# STM32MP21_CA35 register map
File version: 0.4
CPU: CM33 r0p1, little endian, MPU, FPU, vendor SysTick, 8 interrupt priority bits
Registers are 32-bit, read-write, reset 0x0 unless marked. A register's access mark holds for its fields unless they carry their own. Offsets are from the block's base; [hi:lo] are bit positions; {n}, {i} and the like mark numbered series; 'fields as' and 'values as' point back to an identical list.

## RCC (part 2 of 2) — RCC register block
Base 0x44200000
Same registers: RCC_S 0x54200000
0x4E0 RCC_DDRPHYCCFGR — RCC DDRPHYC configuration register
  [1] DDRPHYCEN — DDRPHYC kernel clock enable
    0=Writing 0 disables DDRPHYC kernel clock; 1=Writing 1 enables DDRPHYC kernel clock
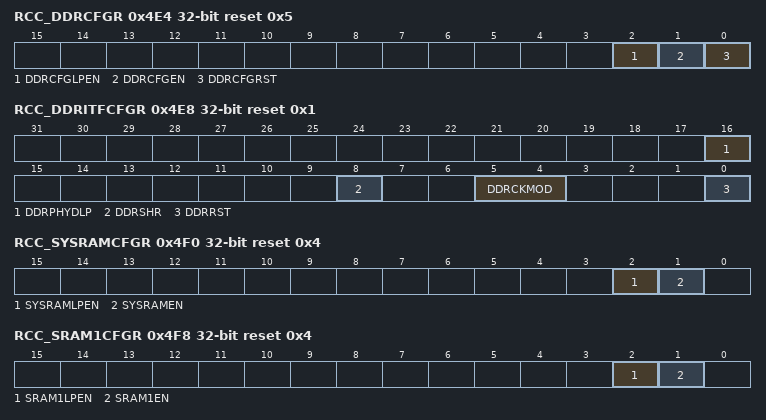
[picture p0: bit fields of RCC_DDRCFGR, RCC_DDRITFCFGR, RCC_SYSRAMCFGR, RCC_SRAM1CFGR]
0x4E4 RCC_DDRCFGR reset 0x5 — RCC DDR configuration register
  [2] DDRCFGLPEN — DDR APB configuration clock enable during CSleep
    0=Writing 0 disables peripheral clocks in CSleep; 1=Writing 1 enables peripheral clocks in CSleep
  [1] DDRCFGEN — DDR APB configuration clock enable
    0=Writing 0 disables peripheral clocks; 1=Writing 1 enables peripheral clocks
  [0] DDRCFGRST — DDR APB configuration reset
    0=Writing 0 releases DDR APB configuration interface reset; 1=Writing 1 sets DDR APB configuration interface under reset
0x4E8 RCC_DDRITFCFGR reset 0x1 — RCC DDR interface configuration register
  [16] DDRPHYDLP — DDRPHY deep low-power mode (LP2 or LP3)
    0=DDRPHY not set in low-power mode (default after reset); 1=DDRPHY set in deep low-power mode
  [8] DDRSHR — DDR peripheral mode
    0=DDR defined as single peripheral (default after reset); 1=DDR defined as shared peripheral
  [5:4] DDRCKMOD — RCC mode for DDR clock control
    0=Normal mode: dphy_ker_ck and dphy_ker_byp_ck gating depends on DDRPHYCEN, DDRSHR, DDRPHYDLP, and CPU1 or system mode; 1=ASR (automatic self-refresh) mode: ddrc_ker_ck is gated automatically according to cactive_ddrc signal; 2=HSR (hardware self-refresh) mode: ddrc_ker_ck gating depends on DDRCPEN, DDRCLPEN, DDRSHR, and CPU1 or system mode
  [0] DDRRST — DDR core and PHY reset
    0=DDR core and PHY are not reset; 1=DDR core and PHY are reset (default after reset)
0x4F0 RCC_SYSRAMCFGR reset 0x4 — RCC SYSRAM configuration register
  [2] SYSRAMLPEN — SYSRAM clock enable during CSleep
    values as RCC_DDRCFGR.DDRCFGLPEN
  [1] SYSRAMEN — SYSRAM clock enable
    values as RCC_DDRCFGR.DDRCFGEN
0x4F8 RCC_SRAM1CFGR reset 0x4 — RCC SRAM1 configuration register
  [2] SRAM1LPEN — SRAM1 clock enable during CSleep
    values as RCC_DDRCFGR.DDRCFGLPEN
  [1] SRAM1EN — SRAM1 clock enable
    values as RCC_DDRCFGR.DDRCFGEN
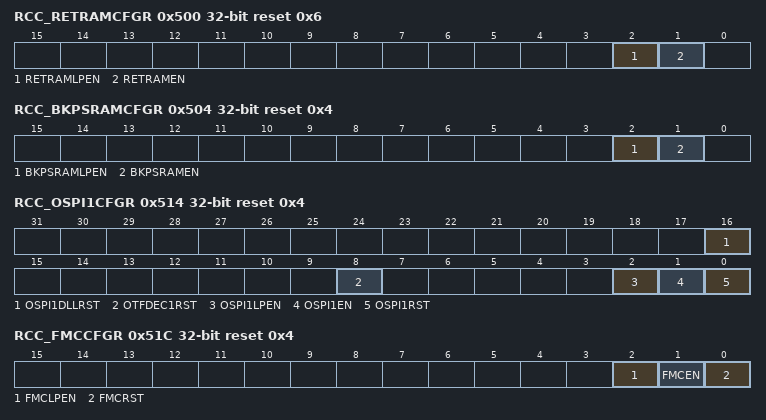
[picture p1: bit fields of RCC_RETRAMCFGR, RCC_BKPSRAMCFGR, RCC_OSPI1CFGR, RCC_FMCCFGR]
0x500 RCC_RETRAMCFGR reset 0x6 — RCC RETRAM configuration register
  [2] RETRAMLPEN — RETRAM clock enable during CSleep
    values as RCC_DDRCFGR.DDRCFGLPEN
  [1] RETRAMEN — RETRAM clock enable
    values as RCC_DDRCFGR.DDRCFGEN
0x504 RCC_BKPSRAMCFGR reset 0x4 — RCC BKPSRAM configuration register
  [2] BKPSRAMLPEN — BKPSRAM clock enable during CSleep
    values as RCC_DDRCFGR.DDRCFGLPEN
  [1] BKPSRAMEN — BKPSRAM clock enable
    values as RCC_DDRCFGR.DDRCFGEN
0x514 RCC_OSPI1CFGR reset 0x4 — RCC OCTOSPI1 configuration register
  [16] OSPI1DLLRST — OCTOSPI1 DLL reset
    0=Writing 0 releases OCTOSPI1 DLL reset; 1=Writing 1 asserts OCTOSPI1 DLL reset
  [8] OTFDEC1RST — OTFDEC1 reset
    0=Writing 0 releases OTFDEC1 reset; 1=Writing 1 asserts OTFDEC1 reset
  [2] OSPI1LPEN — OCTOSPI1, OTFDEC1 and OCTOSPI1 delay (DLYBOSPI1) clock enable duringCSleep
    values as RCC_DDRCFGR.DDRCFGLPEN
  [1] OSPI1EN — OCTOSPI1 and OTFDEC1 clock enable
    values as RCC_DDRCFGR.DDRCFGEN
  [0] OSPI1RST — OCTOSPI1 reset
    0=Writing 0 releases OCTOSPI1 reset; 1=Writing 1 asserts OCTOSPI1 reset
0x51C RCC_FMCCFGR reset 0x4 — RCC FMC configuration register
  [2] FMCLPEN — FMC clock enable during CSleep
    values as RCC_DDRCFGR.DDRCFGLPEN
  [1] FMCEN — FMC clock enable
    values as RCC_DDRCFGR.DDRCFGEN
  [0] FMCRST — FMC reset
    0=Writing 0 releases FMC reset; 1=Writing 1 asserts FMC reset
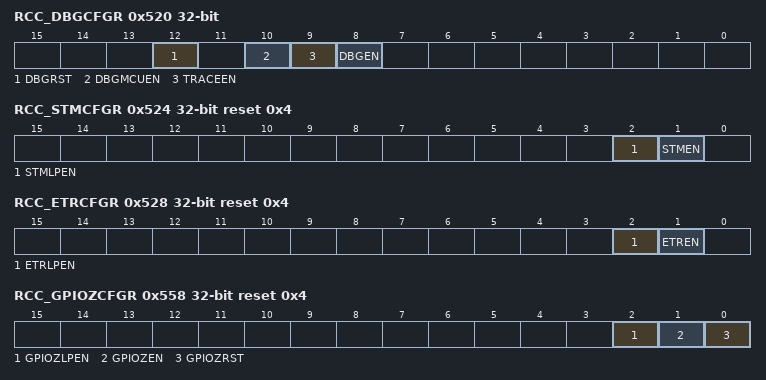
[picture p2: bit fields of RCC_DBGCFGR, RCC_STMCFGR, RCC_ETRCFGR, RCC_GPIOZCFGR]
0x520 RCC_DBGCFGR — RCC debug configuration register
  [12] DBGRST — Debug function reset
    0=Trace and debug parts are not reset (default after reset); 1=Trace and debug parts are under reset
  [10] DBGMCUEN — Clock enable for dbgmcu
    0=Clock for dbgmcu function disabled (default after reset); 1=Clock for dbgmcu function enabled
  [9] TRACEEN — Clock enable for trace port interface
    0=Clock for trace function disabled (default after reset); 1=Clock for trace function enabled
  [8] DBGEN — Debug function clock enable
    0=Enabling of clocks for debug function is controlled by cdbgpwrupreq signal from DAP (default after reset); 1=Clocks for debug function are enabled
0x524 RCC_STMCFGR reset 0x4 — RCC STM configuration register
  [2] STMLPEN — STM clock enable during CSleep
    values as RCC_DDRCFGR.DDRCFGLPEN
  [1] STMEN — STM clock enable
    values as RCC_DDRCFGR.DDRCFGEN
0x528 RCC_ETRCFGR reset 0x4 — RCC ETR configuration register
  [2] ETRLPEN — ETR clock enable during CSleep
    values as RCC_DDRCFGR.DDRCFGLPEN
  [1] ETREN — ETR clocks enable
    values as RCC_DDRCFGR.DDRCFGEN
0x558 RCC_GPIOZCFGR reset 0x4 — RCC GPIOZ configuration register
  [2] GPIOZLPEN — GPIOZ clock enable during CSleep
    values as RCC_DDRCFGR.DDRCFGLPEN
  [1] GPIOZEN — GPIOZ clock enable
    values as RCC_DDRCFGR.DDRCFGEN
  [0] GPIOZRST — GPIOZ reset
    0=Writing 0 releases GPIOZ reset; 1=Writing 1 asserts GPIOZ reset
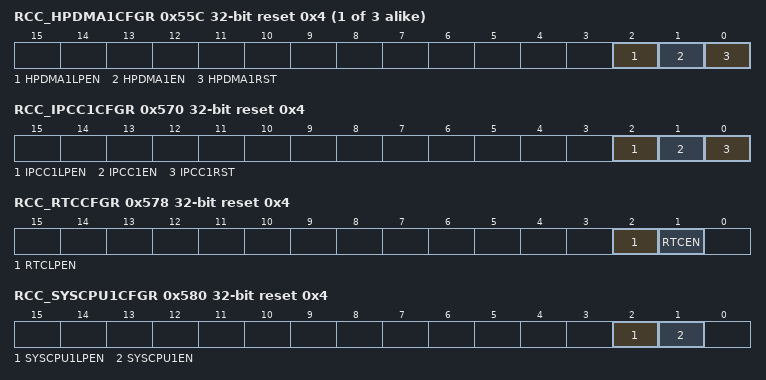
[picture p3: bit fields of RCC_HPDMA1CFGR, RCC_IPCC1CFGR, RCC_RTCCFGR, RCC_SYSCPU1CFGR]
{0x558+4i} RCC_HPDMA{i}CFGR reset 0x4 (i=1..3) — RCC HPDMA{i} configuration register
  [2] HPDMA{i}LPEN — HPDMA{i} clock enable during CSleep
    values as RCC_DDRCFGR.DDRCFGLPEN
  [1] HPDMA{i}EN — HPDMA{i} clock enable
    values as RCC_DDRCFGR.DDRCFGEN
  [0] HPDMA{i}RST — HPDMA{i} reset
    0=Writing 0 releases HPDMA{i} reset; 1=Writing 1 asserts HPDMA{i} reset
0x570 RCC_IPCC1CFGR reset 0x4 — RCC IPCC1 configuration register
  [2] IPCC1LPEN — IPCC1 clock enable during CSleep
    values as RCC_DDRCFGR.DDRCFGLPEN
  [1] IPCC1EN — IPCC1 clock enable
    values as RCC_DDRCFGR.DDRCFGEN
  [0] IPCC1RST — IPCC1 reset
    0=Writing 0 releases IPCC1 reset; 1=Writing 1 asserts IPCC1 reset
0x578 RCC_RTCCFGR reset 0x4 — RCC RTC configuration register
  [2] RTCLPEN — RTC bus clock enable during CSleep
    0=Writing 0 disables APB clock in CSleep; 1=Writing 1 enables APB clock in CSleep
  [1] RTCEN — RTC bus clock enable
    0=Writing 0 disables APB clock; 1=Writing 1 enables APB clock
0x580 RCC_SYSCPU1CFGR reset 0x4 — RCC SYSCPU1 configuration register
  [2] SYSCPU1LPEN — CPU1 system configuration clock enable during CSleep
    values as RCC_RTCCFGR.RTCLPEN
  [1] SYSCPU1EN — CPU1 system configuration clock enable
    values as RCC_RTCCFGR.RTCEN
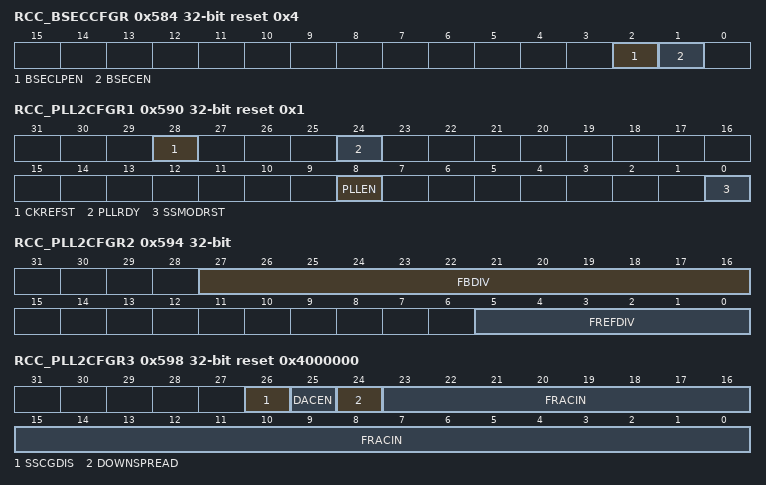
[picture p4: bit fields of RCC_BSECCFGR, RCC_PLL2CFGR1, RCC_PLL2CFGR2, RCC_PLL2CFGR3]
0x584 RCC_BSECCFGR reset 0x4 — RCC BSEC configuration register
  [2] BSECLPEN — BSEC clock enable during CSleep
    values as RCC_RTCCFGR.RTCLPEN
  [1] BSECEN — BSEC clock enable
    values as RCC_RTCCFGR.RTCEN
0x590 RCC_PLL2CFGR1 reset 0x1 — RCC PLL2 configuration register 1
  [28] CKREFST — PLL2 reference clock state
    0=Reading 0 means that PLL2 reference clock is not running; 1=Reading 1 means that PLL2 reference clock is running
  [24] PLLRDY ro — PLL2 clock ready flag
    0=PLL2 unlocked (default after reset); 1=PLL2 locked
  [8] PLLEN — PLL2 enable
    0=PLL2 off (default after reset); 1=PLL2 on
  [0] SSMODRST — PLL2 spread-spectrum modulator reset
    0=PLL2 spread-spectrum modulator reset module is released; 1=PLL2 spread-spectrum modulator reset module is asserted (default after reset)
0x594 RCC_PLL2CFGR2 — RCC PLL2 configuration register 2
  [27:16] FBDIV — PLL2 VCO multiplication factor
  [5:0] FREFDIV — PLL2 reference input clock divide frequency ratio
    0=Not applicable when PLL2 is enabled; 1=FREF divided by 1 (min value); 2=FREF divided by 2; 3=FREF divided by 3; {v}=FREF divided by {v} (v=60..63)
0x598 RCC_PLL2CFGR3 reset 0x4000000 — RCC PLL2 configuration register 3
  [26] SSCGDIS — PLL2 spread-spectrum modulator enable
    0=PLL2 spread-spectrum modulator enabled; 1=PLL2 spread-spectrum modulator disabled (default after reset)
  [25] DACEN — PLL2 noise canceling DAC enable in fractional mode
    0=DAC not active (default after reset); 1=DAC active
  [24] DOWNSPREAD — PLL2 VCO frequency modulation mode
    0=Center-spread modulation selected (default after reset); 1=Down-spread modulation selected
  [23:0] FRACIN — Fractional part of PLL2 VCO multiplication factor
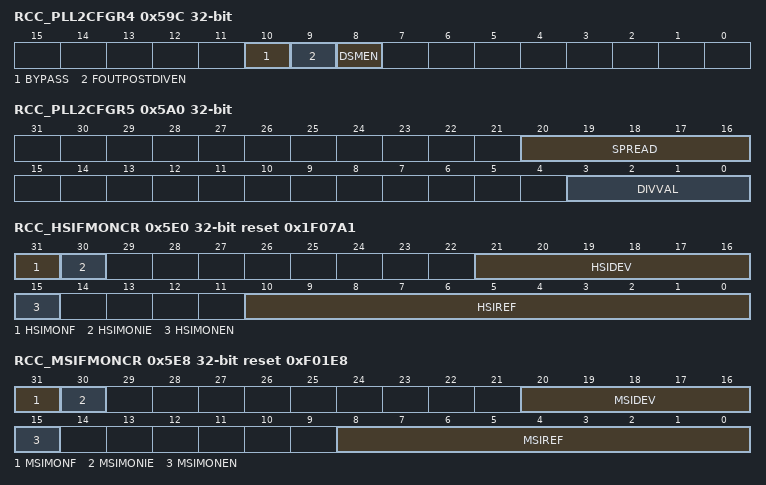
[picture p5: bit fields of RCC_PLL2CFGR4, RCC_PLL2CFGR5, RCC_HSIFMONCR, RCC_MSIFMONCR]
0x59C RCC_PLL2CFGR4 — RCC PLL2 configuration register 4
  [10] BYPASS — PLL2 FOUTPOSTDIV bypass
    0=FOUTPOSTDIV driven by POSTDIV2; 1=FOUTPOSTDIV driven by FREF
  [9] FOUTPOSTDIVEN — PLL2 output and post divider enable
    0=FOUTPOSTDIV output, POSTDIV1, and POSTDIV2 are powered down; 1=FOUTPOSTDIV output, POSTDIV1, and POSTDIV2 dividers are active
  [8] DSMEN — PLL2 delta-sigma modulator enable
    0=DSM is powered down; 1=DSM is active
0x5A0 RCC_PLL2CFGR5 — RCC PLL2 configuration register 5
  [20:16] SPREAD — Modulation depth adjustment for PLL2
  [3:0] DIVVAL — Modulation frequency adjustment for PLL2
0x5A8 RCC_PLL2CFGR6 — RCC PLL2 configuration register 6
  [2:0] POSTDIV1 — PLL2 VCO frequency divide level 1
    0=Not applicable; 1=FOUTVCO divided by 1 (minimum value); 6=FOUTVCO divided by 6; 7=FOUTVCO divided by 7
0x5AC RCC_PLL2CFGR7 — RCC PLL2 configuration register 7
  [2:0] POSTDIV2 — PLL2 VCO frequency divide level 2
    0=Not applicable; 1=FOUTVCO/POSTDIV1 divided by 1 (minimum value); 6=FOUTVCO/POSTDIV1 divided by 6; 7=FOUTVCO/POSTDIV1 divided by 7
0x5E0 RCC_HSIFMONCR reset 0x1F07A1 — RCC HSI frequency monitoring control register
  [31] HSIMONF — HSI clock period monitor interrupt flag
    0=No deviation detected on HSI clock period (default after reset); 1=Deviation detected on HSI clock period
  [30] HSIMONIE — HSI clock period monitor interrupt enable
    0=HSI clock period monitoring interrupt disabled (default after reset); 1=HSI clock period monitoring interrupt enabled
  [21:16] HSIDEV — HSI clock count deviation value
  [15] HSIMONEN — HSI clock period monitor enable
    0=Writing 0 disables HSI clock period monitoring; 1=Writing 1 enables HSI clock period monitoring
  [10:0] HSIREF — HSI clock count reference value
0x5E4 RCC_HSIFVALR ro — RCC HSI frequency value register
  [10:0] HSIVAL — HSI clock-cycle counter value
0x5E8 RCC_MSIFMONCR reset 0xF01E8 — RCC MSI frequency monitoring control register
  [31] MSIMONF — MSI clock period monitor interrupt flag
    0=No deviation detected on MSI clock period (default after reset); 1=Deviation detected on MSI clock period
  [30] MSIMONIE — MSI clock period monitor interrupt enable
    0=MSI clock period monitoring interrupt disabled (default after reset); 1=MSI clock period monitoring interrupt enabled
  [20:16] MSIDEV — MSI clock count deviation value
  [15] MSIMONEN — MSI clock period monitor enable
    0=Writing 0 disables MSI clock period monitoring; 1=Writing 1 enables MSI clock period monitoring
  [8:0] MSIREF — MSI clock count reference value
0x5EC RCC_MSIFVALR ro — RCC MSI frequency value register
  [8:0] MSIVAL — MSI clock-cycle counter value
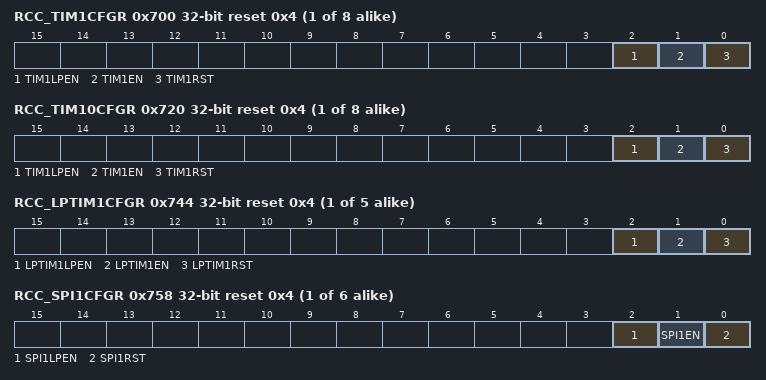
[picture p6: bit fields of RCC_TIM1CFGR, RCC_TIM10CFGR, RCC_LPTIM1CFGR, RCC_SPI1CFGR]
{0x6FC+4i} RCC_TIM{i}CFGR reset 0x4 (i=1..8) — RCC TIM{i} configuration register
  [2] TIM{i}LPEN — TIM{i} clock enable during CSleep
    values as RCC_DDRCFGR.DDRCFGLPEN
  [1] TIM{i}EN — TIM{i} clock enable
    values as RCC_DDRCFGR.DDRCFGEN
  [0] TIM{i}RST — TIM{i} reset
    0=Writing 0 releases TIM{i} reset; 1=Writing 1 asserts TIM{i} reset
{0x6F8+4i} RCC_TIM{i}CFGR reset 0x4 (i=10..17) — RCC TIM{i} configuration register
  fields as RCC_TIM1CFGR
{0x740+4i} RCC_LPTIM{i}CFGR reset 0x4 (i=1..5) — RCC LPTIM{i} configuration register
  [2] LPTIM{i}LPEN — LPTIM{i} clock enable during CSleep
    values as RCC_DDRCFGR.DDRCFGLPEN
  [1] LPTIM{i}EN — LPTIM{i} clock enable
    values as RCC_DDRCFGR.DDRCFGEN
  [0] LPTIM{i}RST — LPTIM{i} reset
    0=Writing 0 releases LPTIM{i} reset; 1=Writing 1 asserts LPTIM{i} reset
{0x754+4i} RCC_SPI{i}CFGR reset 0x4 (i=1..6) — RCC SPI{i} configuration register
  [2] SPI{i}LPEN — SPI{i} clock enable during CSleep
    values as RCC_DDRCFGR.DDRCFGLPEN
  [1] SPI{i}EN — SPI{i} clock enable
    values as RCC_DDRCFGR.DDRCFGEN
  [0] SPI{i}RST — SPI{i} reset
    0=Writing 0 releases SPI{i} reset; 1=Writing 1 asserts SPI{i} reset
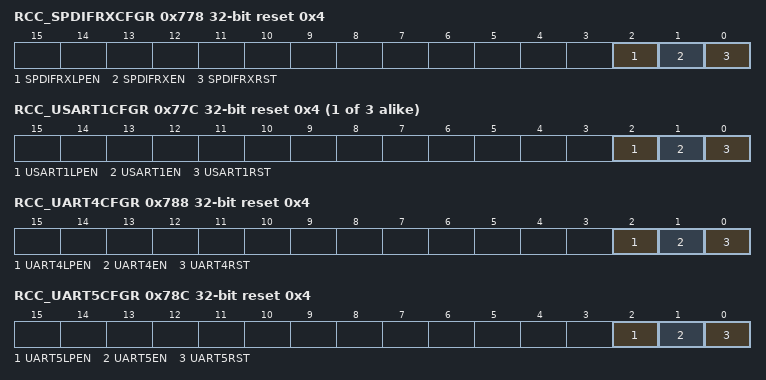
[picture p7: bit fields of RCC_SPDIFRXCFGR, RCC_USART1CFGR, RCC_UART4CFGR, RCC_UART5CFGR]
0x778 RCC_SPDIFRXCFGR reset 0x4 — RCC SPDIFRX configuration register
  [2] SPDIFRXLPEN — SPDIFRX clock enable during CSleep
    values as RCC_DDRCFGR.DDRCFGLPEN
  [1] SPDIFRXEN — SPDIFRX clock enable
    values as RCC_DDRCFGR.DDRCFGEN
  [0] SPDIFRXRST — SPDIFRX reset
    0=Writing 0 releases SPDIFRX reset; 1=Writing 1 asserts SPDIFRX reset
{0x778+4i} RCC_USART{i}CFGR reset 0x4 (i=1..3) — RCC USART{i} configuration register
  [2] USART{i}LPEN — USART{i} clock enable during CSleep
    values as RCC_DDRCFGR.DDRCFGLPEN
  [1] USART{i}EN — USART{i} clock enable
    values as RCC_DDRCFGR.DDRCFGEN
  [0] USART{i}RST — USART{i} reset
    0=Writing 0 releases USART{i} reset; 1=Writing 1 asserts USART{i} reset
0x788 RCC_UART4CFGR reset 0x4 — RCC UART4 configuration register
  [2] UART4LPEN — UART4 clock enable during CSleep
    values as RCC_DDRCFGR.DDRCFGLPEN
  [1] UART4EN — UART4 clock enable
    values as RCC_DDRCFGR.DDRCFGEN
  [0] UART4RST — UART4 reset
    0=Writing 0 releases UART4 reset; 1=Writing 1 asserts UART4 reset
0x78C RCC_UART5CFGR reset 0x4 — RCC UART5 configuration register
  [2] UART5LPEN — UART5 clock enable during CSleep
    values as RCC_DDRCFGR.DDRCFGLPEN
  [1] UART5EN — UART5 clock enable
    values as RCC_DDRCFGR.DDRCFGEN
  [0] UART5RST — UART5 reset
    0=Writing 0 releases UART5 reset; 1=Writing 1 asserts UART5 reset
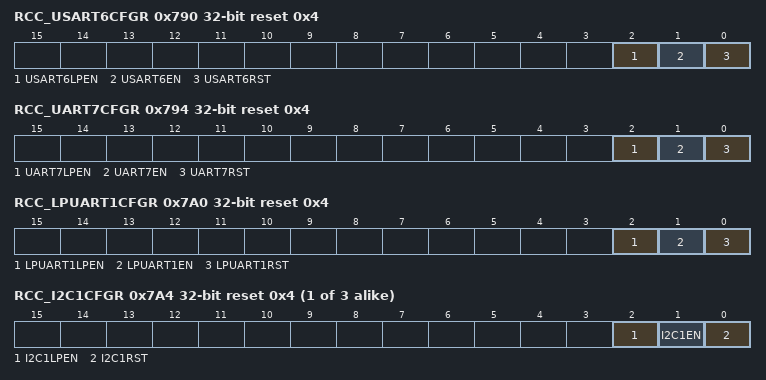
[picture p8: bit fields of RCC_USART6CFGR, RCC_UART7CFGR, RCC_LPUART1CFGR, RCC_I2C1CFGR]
0x790 RCC_USART6CFGR reset 0x4 — RCC USART6 configuration register
  [2] USART6LPEN — USART6 clock enable during CSleep
    values as RCC_DDRCFGR.DDRCFGLPEN
  [1] USART6EN — USART6 clock enable
    values as RCC_DDRCFGR.DDRCFGEN
  [0] USART6RST — USART6 reset
    0=Writing 0 releases USART6 reset; 1=Writing 1 asserts USART6 reset
0x794 RCC_UART7CFGR reset 0x4 — RCC UART7 configuration register
  [2] UART7LPEN — UART7 clock enable during CSleep
    values as RCC_DDRCFGR.DDRCFGLPEN
  [1] UART7EN — UART7 clock enable
    values as RCC_DDRCFGR.DDRCFGEN
  [0] UART7RST — UART7 reset
    0=Writing 0 releases UART7 reset; 1=Writing 1 asserts UART7 reset
0x7A0 RCC_LPUART1CFGR reset 0x4 — RCC LPUART1 configuration register
  [2] LPUART1LPEN — LPUART1 clock enable during CSleep
    values as RCC_DDRCFGR.DDRCFGLPEN
  [1] LPUART1EN — LPUART1 clock enable
    values as RCC_DDRCFGR.DDRCFGEN
  [0] LPUART1RST — LPUART1 reset
    0=Writing 0 releases LPUART1 reset; 1=Writing 1 asserts LPUART1 reset
{0x7A0+4i} RCC_I2C{i}CFGR reset 0x4 (i=1..3) — RCC I2C{i} configuration register
  [2] I2C{i}LPEN — I2C{i} clock enable during CSleep
    values as RCC_DDRCFGR.DDRCFGLPEN
  [1] I2C{i}EN — I2C{i} clock enable
    values as RCC_DDRCFGR.DDRCFGEN
  [0] I2C{i}RST — I2C{i} reset
    0=Writing 0 releases I2C{i} reset; 1=Writing 1 asserts I2C{i} reset
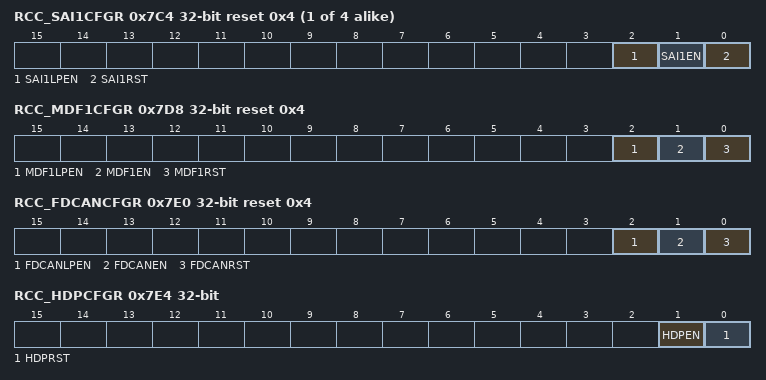
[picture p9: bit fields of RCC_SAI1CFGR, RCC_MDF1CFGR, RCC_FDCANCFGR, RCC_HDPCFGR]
{0x7C0+4i} RCC_SAI{i}CFGR reset 0x4 (i=1..4) — RCC SAI{i} configuration register
  [2] SAI{i}LPEN — SAI{i} clock enable during CSleep
    values as RCC_DDRCFGR.DDRCFGLPEN
  [1] SAI{i}EN — SAI{i} clock enable
    values as RCC_DDRCFGR.DDRCFGEN
  [0] SAI{i}RST — SAI{i} reset
    0=Writing 0 releases SAI{i} reset; 1=Writing 1 asserts SAI{i} reset
0x7D8 RCC_MDF1CFGR reset 0x4 — RCC MDF1 configuration register
  [2] MDF1LPEN — MDF1 clock enable during CSleep
    values as RCC_DDRCFGR.DDRCFGLPEN
  [1] MDF1EN — MDF1 clock enable
    values as RCC_DDRCFGR.DDRCFGEN
  [0] MDF1RST — MDF1 reset
    0=Writing 0 releases MDF1 reset; 1=Writing 1 asserts MDF1 reset
0x7E0 RCC_FDCANCFGR reset 0x4 — RCC FDCAN configuration register
  [2] FDCANLPEN — FDCAN clock enable during CSleep
    values as RCC_DDRCFGR.DDRCFGLPEN
  [1] FDCANEN — FDCAN clock enable
    values as RCC_DDRCFGR.DDRCFGEN
  [0] FDCANRST — FDCAN reset
    0=Writing 0 releases FDCAN reset; 1=Writing 1 asserts FDCAN reset
0x7E4 RCC_HDPCFGR — RCC HDP configuration register
  [1] HDPEN — HDP clock enable
    values as RCC_DDRCFGR.DDRCFGEN
  [0] HDPRST — HDP reset
    0=Writing 0 releases HDP reset; 1=Writing 1 asserts HDP reset
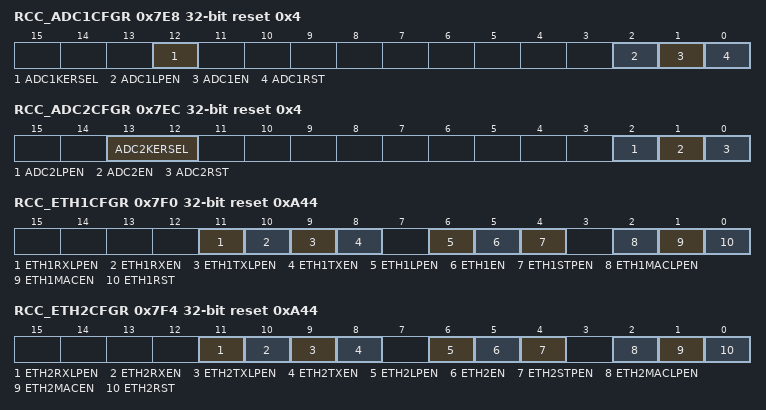
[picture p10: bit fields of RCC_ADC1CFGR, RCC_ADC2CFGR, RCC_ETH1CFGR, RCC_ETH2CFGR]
0x7E8 RCC_ADC1CFGR reset 0x4 — RCC ADC1 configuration register
  [12] ADC1KERSEL — ADC1 kernel clock source select
    0=Kernel source clock is ck_ker_adc1; 1=Kernel source clock is ck_icn_ls_mcu
  [2] ADC1LPEN — ADC1 clock enable during CSleep
    values as RCC_DDRCFGR.DDRCFGLPEN
  [1] ADC1EN — ADC1 clock enable
    values as RCC_DDRCFGR.DDRCFGEN
  [0] ADC1RST — ADC1 reset
    0=Writing 0 releases ADC1 reset; 1=Writing 1 asserts ADC1 reset
0x7EC RCC_ADC2CFGR reset 0x4 — RCC ADC2 configuration register
  [13:12] ADC2KERSEL — ADC2 kernel clock source select
    0=Kernel source clock is ck_ker_adc2; 1=Kernel source clock is ck_icn_ls_mcu; 2=Kernel source clock is ck_ker_adc1
  [2] ADC2LPEN — ADC2 clock enable during CSleep
    values as RCC_DDRCFGR.DDRCFGLPEN
  [1] ADC2EN — ADC2 clock enable
    values as RCC_DDRCFGR.DDRCFGEN
  [0] ADC2RST — ADC2 reset
    0=Writing 0 releases ADC2 reset; 1=Writing 1 asserts ADC2 reset
0x7F0 RCC_ETH1CFGR reset 0xA44 — RCC Ethernet 1 configuration register
  [11] ETH1RXLPEN — Ethernet 1 reception clock enable during CSleep
    0=Writing 0 disables reception clock in CSleep; 1=Writing 1 enables reception clock in CSleep
  [10] ETH1RXEN — Ethernet 1 reception clock enable
    0=Writing 0 disables reception clock; 1=Writing 1 enables reception clock
  [9] ETH1TXLPEN — Ethernet 1 transmission clock enable during CSleep
    0=Writing 0 disables transmission clock in CSleep; 1=Writing 1 enables transmission clock in CSleep
  [8] ETH1TXEN — Ethernet 1 transmission clock enable
    0=Writing 0 disables transmission clock; 1=Writing 1 enables transmission clock
  [6] ETH1LPEN — Ethernet 1 kernel clock enable during CSleep
    0=Writing 0 disables kernel clocks in CSleep; 1=Writing 1 enables kernel clocks in CSleep
  [5] ETH1EN — Ethernet 1 kernel clock enable
    0=Writing 0 disables kernel clocks; 1=Writing 1 enables kernel clocks
  [4] ETH1STPEN — Ethernet 1 kernel clocks enable during CStop
    0=Writing 0 disables ETH1 TX and RX kernel clocks in CStop; 1=Writing 1 enables ETH1 TX and RX kernel clocks in CStop
  [2] ETH1MACLPEN — Ethernet 1 bus clock enable during CSleep
    0=Writing 0 disables bus clocks in CSleep; 1=Writing 1 enables bus clocks in CSleep
  [1] ETH1MACEN — Ethernet 1 bus clock enable
    0=Writing 0 disables bus clocks; 1=Writing 1 enables bus clocks
  [0] ETH1RST — Ethernet 1 reset
    0=Writing 0 releases ETH1 reset; 1=Writing 1 asserts ETH1 reset
0x7F4 RCC_ETH2CFGR reset 0xA44 — RCC Ethernet 2 configuration register
  [11] ETH2RXLPEN — Ethernet 2 reception clock enable during CSleep
    values as RCC_ETH1CFGR.ETH1RXLPEN
  [10] ETH2RXEN — Ethernet 2 reception clock enable
    values as RCC_ETH1CFGR.ETH1RXEN
  [9] ETH2TXLPEN — Ethernet 2 transmission clock enable during CSleep mode
    values as RCC_ETH1CFGR.ETH1TXLPEN
  [8] ETH2TXEN — Ethernet 2 transmission clock enable
    values as RCC_ETH1CFGR.ETH1TXEN
  [6] ETH2LPEN — Ethernet 2 kernel clocks enable during CSleep
    values as RCC_ETH1CFGR.ETH1LPEN
  [5] ETH2EN — Ethernet 2 kernel clocks enable
    values as RCC_ETH1CFGR.ETH1EN
  [4] ETH2STPEN — Ethernet 2 kernel clocks enable during CStop
    0=Writing 0 disables ETH2 TX and RX kernel clocks in CStop; 1=Writing 1 enables ETH2 TX and RX kernel clocks in CStop
  [2] ETH2MACLPEN — Ethernet 2 bus clock enable during CSleep
    values as RCC_ETH1CFGR.ETH1MACLPEN
  [1] ETH2MACEN — Ethernet 2 bus clock enable
    values as RCC_ETH1CFGR.ETH1MACEN
  [0] ETH2RST — Ethernet 2 reset
    0=Writing 0 releases ETH2 reset; 1=Writing 1 asserts ETH2 reset
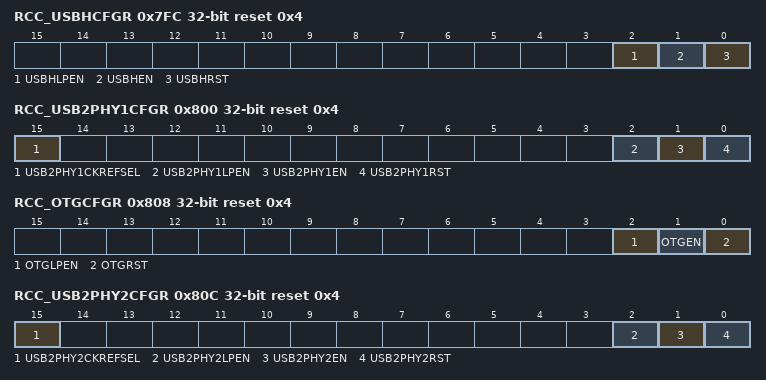
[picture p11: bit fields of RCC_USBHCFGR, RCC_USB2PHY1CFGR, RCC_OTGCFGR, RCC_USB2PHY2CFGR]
0x7FC RCC_USBHCFGR reset 0x4 — RCC USBH configuration register
  [2] USBHLPEN — USBH clock enable during CSleep
    values as RCC_DDRCFGR.DDRCFGLPEN
  [1] USBHEN — USBH peripheral clock enable
    values as RCC_DDRCFGR.DDRCFGEN
  [0] USBHRST — USBH reset
    0=Writing 0 releases USBH reset; 1=Writing 1 asserts USBH reset
0x800 RCC_USB2PHY1CFGR reset 0x4 — RCC USB2PHY1 configuration register
  [15] USB2PHY1CKREFSEL — USB2PHY1 reference clock selection
    0=USB2PHY1 reference clock is channel 57 (ck_ker_usb2phy1) of the flexclkgen; 1=USB2PHY1 reference clock is the HSE oscillator divided by 2 (hse_div2_ck)
  [2] USB2PHY1LPEN — USB2PHY1 clock enable during CSleep
    values as RCC_DDRCFGR.DDRCFGLPEN
  [1] USB2PHY1EN — USB2PHY1 clock enable
    values as RCC_DDRCFGR.DDRCFGEN
  [0] USB2PHY1RST — USB2PHY1 reset
    0=Writing 0 releases USB2PHY1 reset; 1=Writing 1 asserts USB2PHY1 reset
0x808 RCC_OTGCFGR reset 0x4 — RCC OTG configuration register
  [2] OTGLPEN — OTG clock enable during CSleep
    values as RCC_DDRCFGR.DDRCFGLPEN
  [1] OTGEN — OTG peripheral clock enable
    values as RCC_DDRCFGR.DDRCFGEN
  [0] OTGRST — OTG reset
    0=Writing 0 releases OTG reset; 1=Writing 1 asserts OTG reset
0x80C RCC_USB2PHY2CFGR reset 0x4 — RCC USB2PHY2 configuration register
  [15] USB2PHY2CKREFSEL — USB2PHY2 reference clock select
    0=USB2PHY2 reference clock is channel 58 (ck_ker_usb2phy2) of the flexclkgen; 1=USB2PHY2 reference clock is the HSE oscillator divided by 2 (hse_div2_ck)
  [2] USB2PHY2LPEN — USB2PHY2 clock enable during CSleep
    values as RCC_DDRCFGR.DDRCFGLPEN
  [1] USB2PHY2EN — USB2PHY2 clock enable
    values as RCC_DDRCFGR.DDRCFGEN
  [0] USB2PHY2RST — USB2PHY2 reset
    0=Writing 0 releases USB2PHY2 reset; 1=Writing 1 asserts USB2PHY2 reset
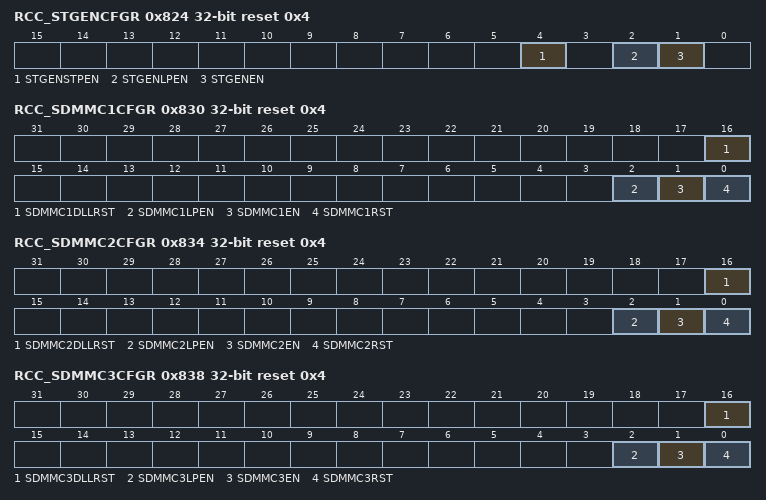
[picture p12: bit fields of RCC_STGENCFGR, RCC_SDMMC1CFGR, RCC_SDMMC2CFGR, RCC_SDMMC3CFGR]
0x824 RCC_STGENCFGR reset 0x4 — RCC STGEN configuration register
  [4] STGENSTPEN — STGENRW and STGENRO kernel clock enable during CStop
    0=Writing 0 disables kernel clocks in CStop; 1=Writing 1 enables kernel clocks in CStop
  [2] STGENLPEN — STGENRW and STGENRO clock enable during CSleep
    values as RCC_DDRCFGR.DDRCFGLPEN
  [1] STGENEN — STGENRW and STGENRO clock enable
    values as RCC_DDRCFGR.DDRCFGEN
0x830 RCC_SDMMC1CFGR reset 0x4 — RCC SDMMC1 configuration register
  [16] SDMMC1DLLRST — SDMMC1 DLL reset
    0=Writing 0 releases DLL reset; 1=Writing 1 asserts DLL reset
  [2] SDMMC1LPEN — SDMMC1 clock enable during CSleep
    values as RCC_DDRCFGR.DDRCFGLPEN
  [1] SDMMC1EN — SDMMC1 clock enable
    values as RCC_DDRCFGR.DDRCFGEN
  [0] SDMMC1RST — SDMMC1 reset
    0=Writing 0 releases SDMMC1 reset; 1=Writing 1 asserts SDMMC1 reset
0x834 RCC_SDMMC2CFGR reset 0x4 — RCC SDMMC2 configuration register
  [16] SDMMC2DLLRST — SDMMC2 DLL reset
    values as RCC_SDMMC1CFGR.SDMMC1DLLRST
  [2] SDMMC2LPEN — SDMMC2 clock enable during CSleep
    values as RCC_DDRCFGR.DDRCFGLPEN
  [1] SDMMC2EN — SDMMC2 clock enable
    values as RCC_DDRCFGR.DDRCFGEN
  [0] SDMMC2RST — SDMMC2 reset
    0=Writing 0 releases SDMMC2 reset; 1=Writing 1 asserts SDMMC2 reset
0x838 RCC_SDMMC3CFGR reset 0x4 — RCC SDMMC3 configuration register
  [16] SDMMC3DLLRST — SDMMC3 DLL reset
    values as RCC_SDMMC1CFGR.SDMMC1DLLRST
  [2] SDMMC3LPEN — SDMMC3 clock enable during CSleep
    values as RCC_DDRCFGR.DDRCFGLPEN
  [1] SDMMC3EN — SDMMC3 clock enable
    values as RCC_DDRCFGR.DDRCFGEN
  [0] SDMMC3RST — SDMMC3 block reset
    0=Writing 0 releases SDMMC3 reset; 1=Writing 1 asserts SDMMC3 reset
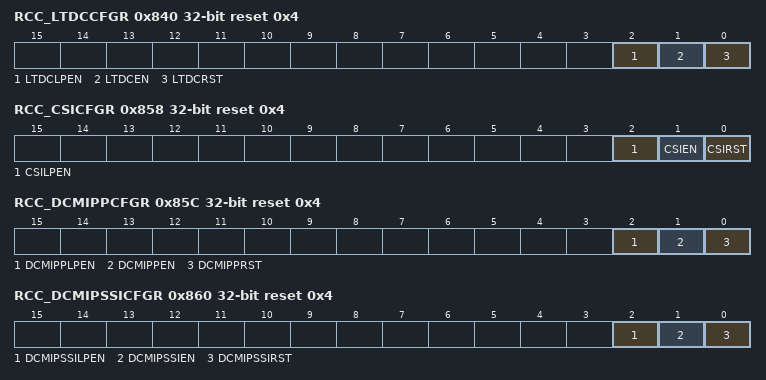
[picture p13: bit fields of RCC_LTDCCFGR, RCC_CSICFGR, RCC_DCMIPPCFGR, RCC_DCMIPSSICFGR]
0x840 RCC_LTDCCFGR reset 0x4 — RCC LTDC configuration register
  [2] LTDCLPEN — LTDC clock enable during CSleep
    values as RCC_DDRCFGR.DDRCFGLPEN
  [1] LTDCEN — LTDC peripheral clock enable
    values as RCC_DDRCFGR.DDRCFGEN
  [0] LTDCRST — LTDC reset
    0=Writing 0 releases LTDC reset; 1=Writing 1 asserts LTDC reset
0x858 RCC_CSICFGR reset 0x4 — RCC CSI configuration register
  [2] CSILPEN — CSI clock enable during CSleep
    values as RCC_DDRCFGR.DDRCFGLPEN
  [1] CSIEN — CSI clock enable
    values as RCC_DDRCFGR.DDRCFGEN
  [0] CSIRST — CSI reset
    0=Writing 0 releases CSI reset; 1=Writing 1 asserts CSI reset
0x85C RCC_DCMIPPCFGR reset 0x4 — RCC DCMIPP configuration register
  [2] DCMIPPLPEN — DCMIPP clock enable during CSleep
    values as RCC_DDRCFGR.DDRCFGLPEN
  [1] DCMIPPEN — DCMIPP clock enable
    values as RCC_DDRCFGR.DDRCFGEN
  [0] DCMIPPRST — DCMIPP reset
    0=Writing 0 releases DCMIPP reset; 1=Writing 1 asserts DCMIPP reset
0x860 RCC_DCMIPSSICFGR reset 0x4 — RCC DCMIPSSI configuration register
  [2] DCMIPSSILPEN — DCMIPSSI clock enable during CSleep
    values as RCC_DDRCFGR.DDRCFGLPEN
  [1] DCMIPSSIEN — DCMIPSSI clock enable
    values as RCC_DDRCFGR.DDRCFGEN
  [0] DCMIPSSIRST — DCMIPSSI reset
    0=Writing 0 releases DCMIPSSI reset; 1=Writing 1 asserts DCMIPSSI reset
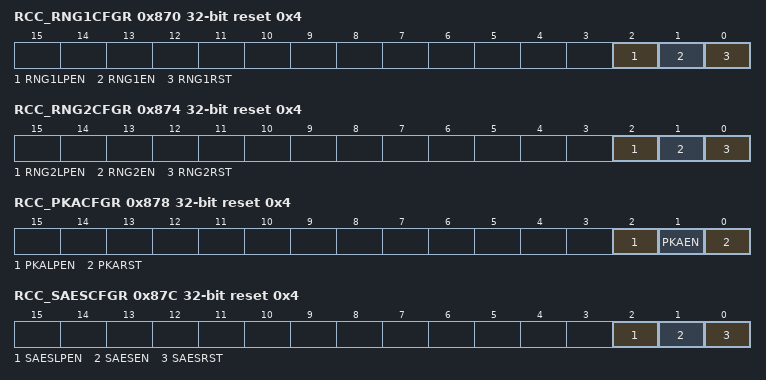
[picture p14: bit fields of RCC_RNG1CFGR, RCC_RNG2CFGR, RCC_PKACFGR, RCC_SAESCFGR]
0x870 RCC_RNG1CFGR reset 0x4 — RCC RNG1 configuration register
  [2] RNG1LPEN — RNG1 clock enable during CSleep
    values as RCC_DDRCFGR.DDRCFGLPEN
  [1] RNG1EN — RNG1 clock enable
    values as RCC_DDRCFGR.DDRCFGEN
  [0] RNG1RST — RNG1 reset
    0=Writing 0 releases RNG1 reset; 1=Writing 1 asserts RNG1 reset
0x874 RCC_RNG2CFGR reset 0x4 — RCC RNG2 configuration register
  [2] RNG2LPEN — RNG2 clock enable during CSleep
    values as RCC_DDRCFGR.DDRCFGLPEN
  [1] RNG2EN — RNG2 clock enable
    values as RCC_DDRCFGR.DDRCFGEN
  [0] RNG2RST — RNG2 reset
    0=Writing 0 releases RNG2 reset; 1=Writing 1 asserts RNG2 reset
0x878 RCC_PKACFGR reset 0x4 — RCC PKA configuration register
  [2] PKALPEN — PKA clock enable during CSleep
    values as RCC_DDRCFGR.DDRCFGLPEN
  [1] PKAEN — PKA clock enable
    values as RCC_DDRCFGR.DDRCFGEN
  [0] PKARST — PKA reset
    0=Writing 0 releases PKA reset; 1=Writing 1 asserts PKA reset
0x87C RCC_SAESCFGR reset 0x4 — RCC SAES configuration register
  [2] SAESLPEN — SAES clock enable during CSleep
    values as RCC_DDRCFGR.DDRCFGLPEN
  [1] SAESEN — SAES clock enable
    values as RCC_DDRCFGR.DDRCFGEN
  [0] SAESRST — SAES reset
    0=Writing 0 releases SAES reset; 1=Writing 1 asserts SAES reset
0x880 RCC_HASH1CFGR reset 0x4 — RCC HASH1 configuration register
  [2] HASH1LPEN — HASH1 clock enable during CSleep
    values as RCC_DDRCFGR.DDRCFGLPEN
  [1] HASH1EN — HASH1 clock enable
    values as RCC_DDRCFGR.DDRCFGEN
  [0] HASH1RST — HASH1 reset
    0=Writing 0 releases HASH1 reset; 1=Writing 1 asserts HASH1 reset
0x884 RCC_HASH2CFGR reset 0x4 — RCC HASH2 configuration register
  [2] HASH2LPEN — HASH2 clock enable during CSleep
    values as RCC_DDRCFGR.DDRCFGLPEN
  [1] HASH2EN — HASH2 clock enable
    values as RCC_DDRCFGR.DDRCFGEN
  [0] HASH2RST — HASH2 reset
    0=Writing 0 releases HASH2 reset; 1=Writing 1 asserts HASH2 reset
0x888 RCC_CRYP1CFGR reset 0x4 — RCC CRYP1 configuration register
  [2] CRYP1LPEN — CRYP1 clock enable during CSleep
    values as RCC_DDRCFGR.DDRCFGLPEN
  [1] CRYP1EN — CRYP1 clock enable
    values as RCC_DDRCFGR.DDRCFGEN
  [0] CRYP1RST — CRYP1 reset
    0=Writing 0 releases CRYP1 reset; 1=Writing 1 asserts CRYP1 reset
0x88C RCC_CRYP2CFGR reset 0x4 — RCC CRYP2 configuration register
  [2] CRYP2LPEN — CRYP2 clock enable during CSleep
    values as RCC_DDRCFGR.DDRCFGLPEN
  [1] CRYP2EN — CRYP2 clock enable
    values as RCC_DDRCFGR.DDRCFGEN
  [0] CRYP2RST — CRYP2 reset
    0=Writing 0 releases CRYP2 reset; 1=Writing 1 asserts CRYP2 reset
{0x890+4i} RCC_IWDG{i}CFGR reset 0x4 (i=1..4) — RCC IWDG{i} configuration register
  [2] IWDG{i}LPEN — IWDG{i} bus clock enable during CSleep
    values as RCC_RTCCFGR.RTCLPEN
  [1] IWDG{i}EN — IWDG{i} bus clock enable
    values as RCC_RTCCFGR.RTCEN
0x8A4 RCC_WWDG1CFGR reset 0x4 — RCC WWDG1 configuration register
  [2] WWDG1LPEN — WWDG1 bus clock enable during CSleep
    values as RCC_RTCCFGR.RTCLPEN
  [1] WWDG1EN — WWDG1 bus clock enable
    values as RCC_RTCCFGR.RTCEN
  [0] WWDG1RST — WWDG1 reset
    0=Writing 0 releases WWDG1 reset; 1=Writing 1 asserts WWDG1 reset
0x8AC RCC_VREFCFGR reset 0x4 — RCC VREFBUF configuration register
  [2] VREFLPEN — VREFBUF clock enable during CSleep
    values as RCC_DDRCFGR.DDRCFGLPEN
  [1] VREFEN — VREFBUF clock enable
    values as RCC_DDRCFGR.DDRCFGEN
  [0] VREFRST — VREFBUF reset
    0=Writing 0 releases VREFBUF reset; 1=Writing 1 asserts VREFBUF reset
0x8B0 RCC_DTSCFGR reset 0x4 — RCC DTS configuration register
  [13:12] DTSKERSEL — DTS kernel clock selection
    0=hsi_ker_ck selected; 1=hse_ker_ck selected; 2=msi_ker_ck selected
  [2] DTSLPEN — DTS clock enable during CSleep
    values as RCC_DDRCFGR.DDRCFGLPEN
  [1] DTSEN — DTS clock enable
    values as RCC_DDRCFGR.DDRCFGEN
  [0] DTSRST — DTS reset
    0=Writing 0 releases DTS reset; 1=Writing 1 asserts DTS reset
0x8B4 RCC_CRCCFGR reset 0x4 — RCC CRC configuration register
  [2] CRCLPEN — CRC clock enable during CSleep
    values as RCC_DDRCFGR.DDRCFGLPEN
  [1] CRCEN — CRC clock enable
    values as RCC_DDRCFGR.DDRCFGEN
  [0] CRCRST — CRC reset
    0=Writing 0 releases CRC reset; 1=Writing 1 asserts CRC reset
0x8B8 RCC_SERCCFGR reset 0x4 — RCC SERC configuration register
  [2] SERCLPEN — SERC clock enable during CSleep
    values as RCC_DDRCFGR.DDRCFGLPEN
  [1] SERCEN — SERC clocks enable
    values as RCC_DDRCFGR.DDRCFGEN
  [0] SERCRST — SERC reset
    0=Writing 0 releases SERC reset; 1=Writing 1 asserts SERC reset
0x8C0 RCC_DDRPERFMCFGR reset 0x4 — RCC DDRPERFM configuration register
  [2] DDRPERFMLPEN — DDRPERFM clock enable during CSleep
    values as RCC_DDRCFGR.DDRCFGLPEN
  [1] DDRPERFMEN — DDRPERFM clock enable
    values as RCC_DDRCFGR.DDRCFGEN
  [0] DDRPERFMRST — DDRPERFM reset
    0=Writing 0 releases DDRPERFM reset; 1=Writing 1 asserts DDRPERFM reset
{0x8C4+4i} RCC_I3C{i}CFGR reset 0x4 (i=1..3) — RCC I3C{i} configuration register
  [2] I3C{i}LPEN — I3C{i} clock enable during CSleep
    values as RCC_DDRCFGR.DDRCFGLPEN
  [1] I3C{i}EN — I3C{i} clock enable
    values as RCC_DDRCFGR.DDRCFGEN
  [0] I3C{i}RST — I3C{i} reset
    0=Writing 0 releases I3C{i} reset; 1=Writing 1 asserts I3C{i} reset
0x1000 RCC_MUXSELCFGR — RCC MUXSEL configuration register
  [25:24] MUXSEL6 — PLL2 reference clock selection (ck_pll2_ref)
    0=hsi_ck; 1=hse_ck; 2=msi_ck
  [21:20] MUXSEL5 — PLL1 reference clock selection (ck_pll1_ref)
    0=hsi_ck; 1=hse_ck; 2=msi_ck
  [4n+2:4n] MUXSEL{n} (n=0..4) — PLL{n+4} reference clock selection
    0=hsi_ck; 1=hse_ck; 2=msi_ck; 5=ck_in
{0x1018+4i} RCC_XBAR{i}CFGR reset 0x45 (i=0..63) — RCC cross bar {i} configuration register
  [7] XBAR{i}STS ro — Cross bar channel x output status
    0=Channel x is aligned to given settings; 1=Indicates change ongoing
  [6] XBAR{i}EN — Cross bar channel x clock output enable
    0=Channel x output disabled; 1=Channel x output enabled
  [3:0] XBAR{i}SEL — Cross bar channel x input clock selection
    {v}=PLL{v+4} FOUTPOSTDIV clock selected (v=0..4); 5=hsi_ck selected; 6=hse_ck selected; 7=msi_ck selected; 8=hsi_ker_ck selected; 9=hse_ker_ck selected; 10=msi_ker_ck selected; 11=spdifrx_symb_ck selected; 12=ck_in selected; 13=lsi_ck selected; 14=lse_ck selected
{0x1118+4i} RCC_PREDIV{i}CFGR (i=0..63) — RCC pre divider {i} configuration register
  [9:0] PREDIV{i} — Predivider channel x divider ratio
    0=div1; 1=div2; 3=div4; 0x3FF=div1024
0x1218 RCC_PREDIVSR1 ro — RCC pre divider status register 1
  [31:0] PREDIVSTS — Predivider channel[31:0] output status
    0=Channel is aligned with divide ratio change; 1=Indicates that the divider is in the process of changing
0x121C RCC_PREDIVSR2 ro — RCC pre divider status register 2
  [31:0] PREDIVSTS — Predivider channel[63:32] output status
    values as RCC_PREDIVSR1.PREDIVSTS
{0x1224+4i} RCC_FINDIV{i}CFGR reset 0x40 (i=0..63) — RCC final divider {i} configuration register
  [6] FINDIV{i}EN — Final divider channel x output enable
    0=Channel x output disabled; 1=Channel x output enabled
  [5:0] FINDIV{i} — Channel x divider ratio
0x1324 RCC_FINDIVSR1 ro — RCC final divider status register 1
  [31:0] FINDIVSTS — Final divider channel[31:0] output status
    values as RCC_PREDIVSR1.PREDIVSTS
0x1328 RCC_FINDIVSR2 ro — RCC final divider status register 2
  [31:0] FINDIVSTS — Final divider channel[63:32] output status
    values as RCC_PREDIVSR1.PREDIVSTS
0x1340 RCC_FCALCOBS0CFGR reset 0x16000087 — RCC clock frequency calculator and observation 0 clock configuration register
  [26] CKOBSEN — Observation clock 0 output enable
    0=Observation clock 0 output disabled; 1=Observation clock 0 output enabled (default after reset)
  [25] FCALCCKEN — Clock frequency calculator input clock enable
    0=Input clock disabled; 1=Input clock enabled (default after reset)
  [24:22] CKOBSDIV — Observation clock 0 divide ratio
    0=div1 (default after reset); 1=div2; 2=div4; 3=div8; 4=div16; 5=div32; 6=div64; 7=div128
  [18] CKOBSINV — Observation clock 0 inverter
    0=Observation clock 0 not inverted (default after reset); 1=Observation clock 0 inverted
  [17] FCALCCKINV — Clock frequency calculator input clock inverter
    0=Input clock not inverted (default after reset); 1=Input clock inverted
  [16] CKOBSEXTSEL — External clock source for observation clock 0
    0=Internal clock selected for observation clock 0 (default after reset); 1=External clock selected for observation clock 0
  [15] FCALCCKEXTSEL — External clock source for clock frequency calculator input clock
    0=Internal clock selected for the clock frequency calculator input clock (default after reset); 1=External clock selected for the clock frequency calculator input clock
  [10:8] CKEXTSEL — External clock selector for clock frequency calculator and
    0=pll1 clock divided by 42; 1=pll2 clock divided by 8; 3=usb2phy1 PLL clock; 4=usb2phy2 PLL clock
  [7:0] CKINTSEL — Internal clock selector for clock frequency calculator and observation clock 0
    0=hsi_ck; 1=hse_ck; 2=msi_ck; {v}=PLL{v-2} reference input clock (v=6..10); 11=PLL1 reference input clock; 12=PLL2 reference input clock; {v}=PLL{v-60} output clock (v=64..68); 128=hsi_ker_ck; 129=hse_ker_ck; 130=msi_ker_ck; 131=spdifrx_symb_ck; 132=ck_in; 133=lsi_ck; 134=lse_ck; 135=ck_xbar_fsm (default after reset); 136=ck_icn_p_rcc; 192=findiv[0]; 193=findiv[1]; 255=findiv[63]
0x1344 RCC_FCALCOBS1CFGR reset 0x6000087 — RCC clock frequency calculator and observation 1 clock configuration register
  [27] FCALCRSTN — Clock frequency calculator reset
    0=Clock frequency calculator reset module asserted (default after reset); 1=Clock frequency calculator reset module released
  [26] CKOBSEN — Observation clock 1 output enable
    0=Observation clock 1 output disabled; 1=Observation clock 1 output enabled (default after reset)
  [24:22] CKOBSDIV — Observation clock 1 divide ratio
    values as RCC_FCALCOBS0CFGR.CKOBSDIV
  [18] CKOBSINV — Observation clock 1 inverter
    0=Observation clock 1 not inverted (default after reset); 1=Observation clock 1 inverted
  [16] CKOBSEXTSEL — External clock source for the observation clock 1
    0=Internal clock selected for observation clock 1(default after reset); 1=External clock selected for observation clock 1
  [10:8] CKEXTSEL — External clock for observation clock 1
    values as RCC_FCALCOBS0CFGR.CKEXTSEL
  [7:0] CKINTSEL — Internal clock selector for observation clock 1
    values as RCC_FCALCOBS0CFGR.CKINTSEL
0x1348 RCC_FCALCREFCFGR reset 0x4000 — RCC clock frequency calculator reference clock configuration register
  [2:0] FCALCREFCKSEL — Reference clock selection used by clock frequency calculator
    {v}=PLL{v+4} reference input clock (v=0..4)
0x134C RCC_FCALCCR1 — RCC clock frequency calculator control register 1
  [0] FCALCRUN — Clock frequency calculator run
    0=Clock frequency calculator off (default after reset); 1=Clock frequency calculator on
0x1354 RCC_FCALCCR2 — RCC clock frequency calculator control register 2
  [21:17] FCALCTYP — Clock frequency calculation type selection
    12=Frequency value type
  [14:11] FCALCTWC — Time window code for clock frequency calculation
    0=63 cycles; 1=3 cycles; 2=7 cycles; 3=15 cycles; 4=31 cycles; 5=63 cycles; 6=127 cycles; 7=255 cycles; 8=511 cycles; 9=1023 cycles; 10=2047 cycles; 11=4095 cycles; 12=8191 cycles; 13=16383 cycles; 14=32767 cycles; 15=65535 cycles
  [4:3] FCALCMD — Clock frequency calculation method
    3=Application method
0x1358 RCC_FCALCSR ro — RCC clock frequency calculator status register
  [19] FCALCSTS — Clock frequency calculation status
  [16:0] FVAL — Clock frequency calculation value
{0x12C0+0x28*i} RCC_PLL{i}CFGR1 reset 0x10000001 (i=4..8) — RCC PLL{i} configuration register 1
  [28] CKREFST — PLLy reference clock state
    0=Reading 0 means that PLLy reference clock does not run; 1=Reading 1 means that PLLy reference clock is running
  [24] PLLRDY ro — PLLy clock ready flag
    0=PLLy unlocked (default after reset); 1=PLLy locked
  [8] PLLEN — PLLy enable
    0=PLLy off (default after reset); 1=PLLy on
  [0] SSMODRST — PLLy spread-spectrum modulator reset
    0=PLLy spread-spectrum modulator reset module released; 1=PLLy spread-spectrum modulator reset module asserted (default after reset)
{0x12C4+0x28*i} RCC_PLL{i}CFGR2 (i=4..8) — RCC PLL{i} configuration register 2
  [27:16] FBDIV — PLLy VCO multiplication factor
  [5:0] FREFDIV — PLLy reference input clock divide frequency ratio
    0=Not applicable; 1=FREF divided by 1 (min value); 2=FREF divided by 2; 3=FREF divided by 3; {v}=FREF divided by {v} (v=60..63)
{0x12C8+0x28*i} RCC_PLL{i}CFGR3 reset 0x4000000 (i=4..8) — RCC PLL{i} configuration register 3
  [26] SSCGDIS — PLLy spread-spectrum modulator disable
    0=PLLy spread-spectrum modulator enabled; 1=PLLy spread-spectrum modulator disabled (default after reset)
  [25] DACEN — PLLy noise canceling DAC enable in fractional mode.
    0=DAC not active (default after reset); 1=DAC active
  [24] DOWNSPREAD — PLLy VCO frequency modulation mode
    values as RCC_PLL2CFGR3.DOWNSPREAD
  [23:0] FRACIN — Fractional part of PLLy VCO multiplication factor
{0x12CC+0x28*i} RCC_PLL{i}CFGR4 (i=4..8) — RCC PLL{i} configuration register 4
  [10] BYPASS — PLLy FOUTPOSTDIV bypass
    values as RCC_PLL2CFGR4.BYPASS
  [9] FOUTPOSTDIVEN — PLLy output and post dividers enable
    values as RCC_PLL2CFGR4.FOUTPOSTDIVEN
  [8] DSMEN — PLLy delta-sigma modulator enable
    0=DSM powered down; 1=DSM active
{0x12D0+0x28*i} RCC_PLL{i}CFGR5 (i=4..8) — RCC PLL{i} configuration register 5
  [20:16] SPREAD — Modulation depth adjustment for PLLy
  [3:0] DIVVAL — Modulation frequency adjustment for PLLy
{0x12D8+0x28*i} RCC_PLL{i}CFGR6 (i=4..8) — RCC PLL{i} configuration register 6
  [2:0] POSTDIV1 — PLLy VCO frequency divide level 1
    0=Not applicable; 1=FOUTVCO divided by 1 (minimum value); {v}=FOUTVCO divided by {v} (v=2..7)
{0x12DC+0x28*i} RCC_PLL{i}CFGR7 (i=4..8) — RCC PLL{i} configuration register 7
  [2:0] POSTDIV2 — PLLy VCO frequency divide level 2
    0=Not applicable; 1=FOUTVCO/POSTDIV1 divided by 1 (minimum value); {v}=FOUTVCO/POSTDIV1 divided by {v} (v=2..7)
0xFFF4 RCC_VERR ro reset 0x10 — RCC version register
  [7:4] MAJREV — Major RCC revision
  [3:0] MINREV — Minor RCC revision
0xFFF8 RCC_IDR ro reset 0x3 — RCC identifier register
  [31:0] ID — RCC identifier
0xFFFC RCC_SIDR ro reset 0xA3C5DD40 — RCC size identification register
  [31:0] SID — RCC decoding space (64 Kbytes)
